# ioam3358 register map
Registers are 32-bit, access not given, no defined reset value unless marked. A register's access mark holds for its fields unless they carry their own. Addresses are absolute; registers are grouped by the start of their names; [hi:lo] are bit positions; {n}, {i} and the like mark numbered series; 'fields as' and 'values as' point back to an identical list.

## I2C2
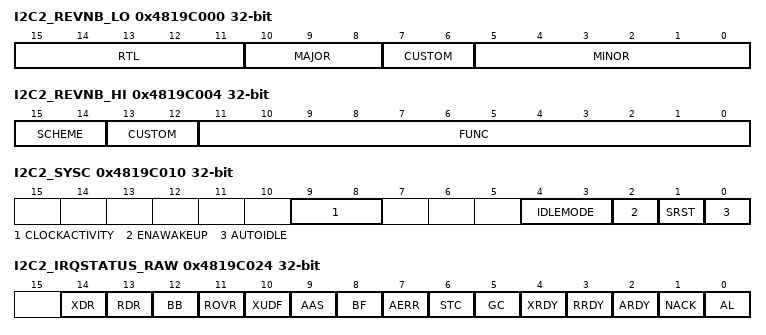
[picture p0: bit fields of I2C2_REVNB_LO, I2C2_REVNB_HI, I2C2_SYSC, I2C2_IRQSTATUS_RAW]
0x4819C000 I2C2_REVNB_LO
  [15:11] RTL, [10:8] MAJOR, [7:6] CUSTOM, [5:0] MINOR
0x4819C004 I2C2_REVNB_HI
  [15:14] SCHEME, [13:12] CUSTOM, [11:0] FUNC
0x4819C010 I2C2_SYSC
  [9:8] CLOCKACTIVITY, [4:3] IDLEMODE, [2] ENAWAKEUP, [1] SRST, [0] AUTOIDLE
0x4819C020 I2C2_EOI
  [0] LINE_NUMBER
0x4819C024 I2C2_IRQSTATUS_RAW
  [14] XDR, [13] RDR, [12] BB, [11] ROVR, [10] XUDF, [9] AAS, [8] BF, [7] AERR, [6] STC, [5] GC, [4] XRDY, [3] RRDY, [2] ARDY, [1] NACK, [0] AL
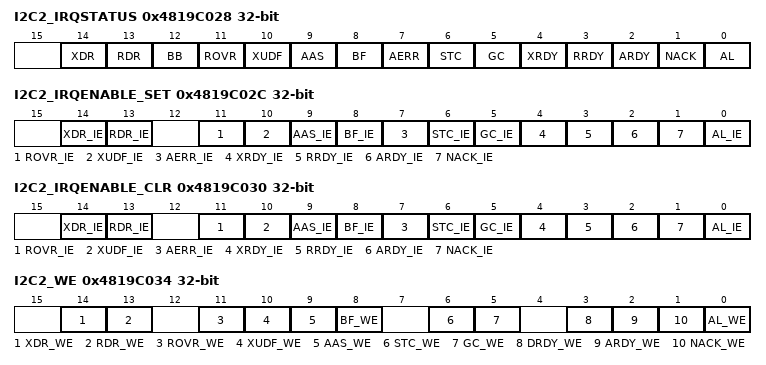
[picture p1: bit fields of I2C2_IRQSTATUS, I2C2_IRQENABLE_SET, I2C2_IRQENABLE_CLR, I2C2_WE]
0x4819C028 I2C2_IRQSTATUS
  fields as I2C2_IRQSTATUS_RAW
0x4819C02C I2C2_IRQENABLE_SET
  [14] XDR_IE, [13] RDR_IE, [11] ROVR_IE, [10] XUDF_IE, [9] AAS_IE, [8] BF_IE, [7] AERR_IE, [6] STC_IE, [5] GC_IE, [4] XRDY_IE, [3] RRDY_IE, [2] ARDY_IE, [1] NACK_IE, [0] AL_IE
0x4819C030 I2C2_IRQENABLE_CLR
  fields as I2C2_IRQENABLE_SET
0x4819C034 I2C2_WE
  [14] XDR_WE, [13] RDR_WE, [11] ROVR_WE, [10] XUDF_WE, [9] AAS_WE, [8] BF_WE, [6] STC_WE, [5] GC_WE, [3] DRDY_WE, [2] ARDY_WE, [1] NACK_WE, [0] AL_WE
0x4819C038 I2C2_DMARXENABLE_SET
  [0] DMARX_ENABLE_SET
0x4819C03C I2C2_DMATXENABLE_SET
  [0] DMATX_ENABLE_SET
0x4819C040 I2C2_DMARXENABLE_CLR
  [0] DMARX_ENABLE_CLEAR
0x4819C044 I2C2_DMATXENABLE_CLR
  [0] DMARX_ENABLE_CLEAR
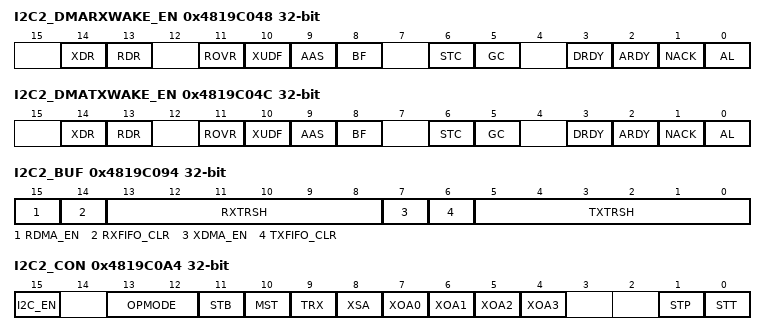
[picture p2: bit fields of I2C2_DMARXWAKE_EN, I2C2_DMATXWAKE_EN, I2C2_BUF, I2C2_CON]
0x4819C048 I2C2_DMARXWAKE_EN
  [14] XDR, [13] RDR, [11] ROVR, [10] XUDF, [9] AAS, [8] BF, [6] STC, [5] GC, [3] DRDY, [2] ARDY, [1] NACK, [0] AL
0x4819C04C I2C2_DMATXWAKE_EN
  fields as I2C2_DMARXWAKE_EN
0x4819C090 I2C2_SYSS
  [0] RDONE
0x4819C094 I2C2_BUF
  [15] RDMA_EN, [14] RXFIFO_CLR, [13:8] RXTRSH, [7] XDMA_EN, [6] TXFIFO_CLR, [5:0] TXTRSH
0x4819C098 I2C2_CNT
  [15:0] DCOUNT
0x4819C09C I2C2_DATA
  [7:0] DATA
0x4819C0A4 I2C2_CON
  [15] I2C_EN, [13:12] OPMODE, [11] STB, [10] MST, [9] TRX, [8] XSA, [7-n] XOA{n} (n=0..3), [1] STP, [0] STT
0x4819C0A8 I2C2_OA
  [9:0] OA
0x4819C0AC I2C2_SA
  [9:0] SA
0x4819C0B0 I2C2_PSC
  [7:0] PSC
0x4819C0B4 I2C2_SCLL
  [7:0] SCLL
0x4819C0B8 I2C2_SCLH
  [7:0] SCLH
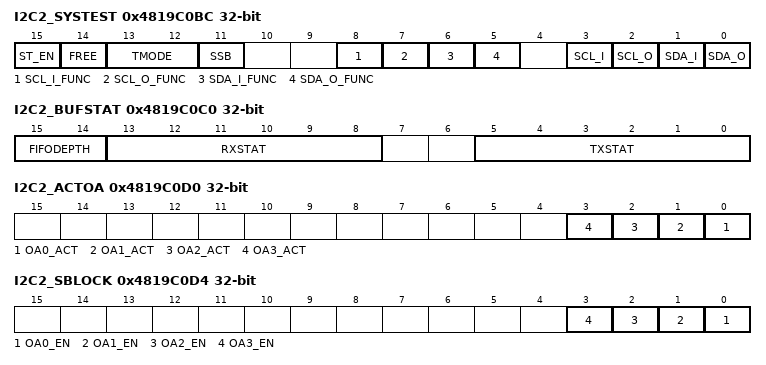
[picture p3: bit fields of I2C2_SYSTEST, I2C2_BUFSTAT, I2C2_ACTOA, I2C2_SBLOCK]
0x4819C0BC I2C2_SYSTEST
  [15] ST_EN, [14] FREE, [13:12] TMODE, [11] SSB, [8] SCL_I_FUNC, [7] SCL_O_FUNC, [6] SDA_I_FUNC, [5] SDA_O_FUNC, [3] SCL_I, [2] SCL_O, [1] SDA_I, [0] SDA_O
0x4819C0C0 I2C2_BUFSTAT
  [15:14] FIFODEPTH, [13:8] RXSTAT, [5:0] TXSTAT
{0x4819C0C0+4i} I2C2_OA{i} (i=1..3)
  [9:0] OA{i}
0x4819C0D0 I2C2_ACTOA
  [n] OA{n}_ACT (n=0..3)
0x4819C0D4 I2C2_SBLOCK
  [n] OA{n}_EN (n=0..3)

## McASP0
0x46000000 McASP0_RBUF
0x46000000 McASP0_XBUF
0x48038000 McASP0_REV
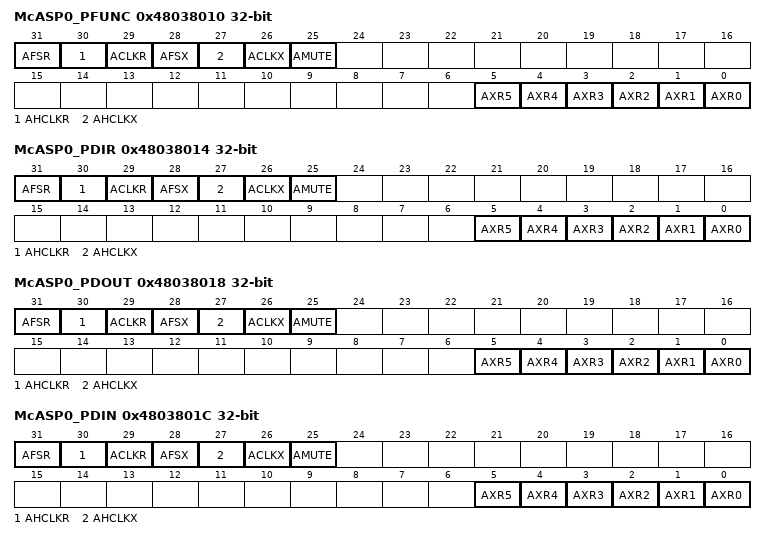
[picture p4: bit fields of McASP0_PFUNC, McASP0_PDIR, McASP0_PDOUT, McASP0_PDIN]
0x48038010 McASP0_PFUNC
  [31] AFSR, [30] AHCLKR, [29] ACLKR, [28] AFSX, [27] AHCLKX, [26] ACLKX, [25] AMUTE, [n] AXR{n} (n=0..5)
0x48038014 McASP0_PDIR
  fields as McASP0_PFUNC
0x48038018 McASP0_PDOUT
  fields as McASP0_PFUNC
0x4803801C McASP0_PDIN
  fields as McASP0_PFUNC
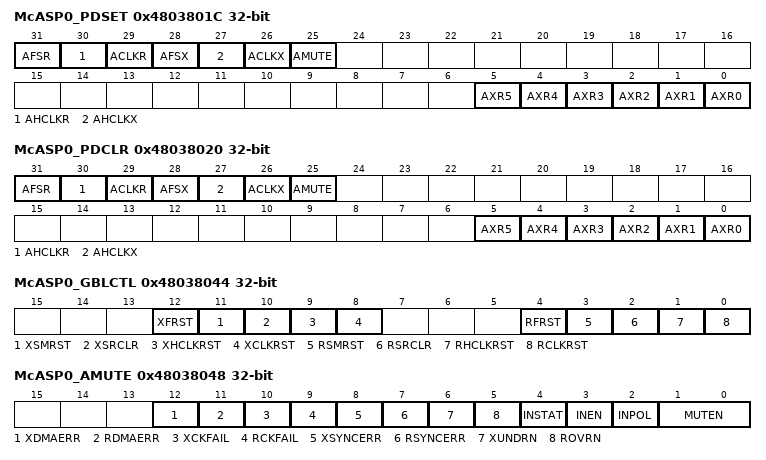
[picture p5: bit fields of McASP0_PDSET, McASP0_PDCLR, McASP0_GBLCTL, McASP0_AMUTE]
0x4803801C McASP0_PDSET
  fields as McASP0_PFUNC
0x48038020 McASP0_PDCLR
  fields as McASP0_PFUNC
0x48038044 McASP0_GBLCTL
  [12] XFRST, [11] XSMRST, [10] XSRCLR, [9] XHCLKRST, [8] XCLKRST, [4] RFRST, [3] RSMRST, [2] RSRCLR, [1] RHCLKRST, [0] RCLKRST
0x48038048 McASP0_AMUTE
  [12] XDMAERR, [11] RDMAERR, [10] XCKFAIL, [9] RCKFAIL, [8] XSYNCERR, [7] RSYNCERR, [6] XUNDRN, [5] ROVRN, [4] INSTAT, [3] INEN, [2] INPOL, [1:0] MUTEN
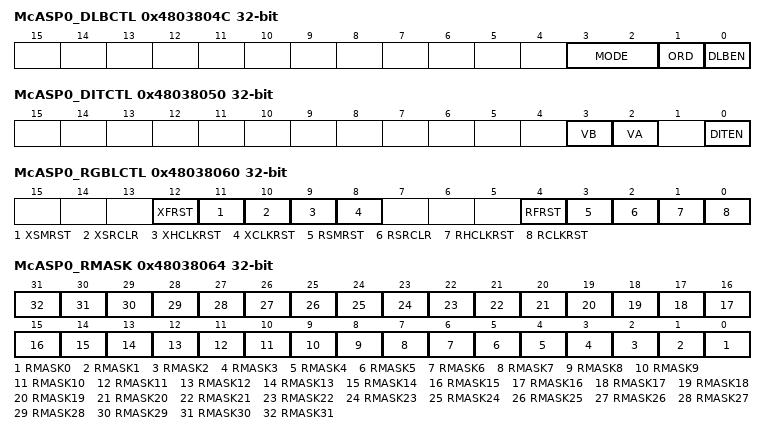
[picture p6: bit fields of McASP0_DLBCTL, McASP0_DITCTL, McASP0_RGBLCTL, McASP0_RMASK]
0x4803804C McASP0_DLBCTL
  [3:2] MODE, [1] ORD, [0] DLBEN
0x48038050 McASP0_DITCTL
  [3] VB, [2] VA, [0] DITEN
0x48038060 McASP0_RGBLCTL
  fields as McASP0_GBLCTL
0x48038064 McASP0_RMASK
  [n] RMASK{n} (n=0..31)
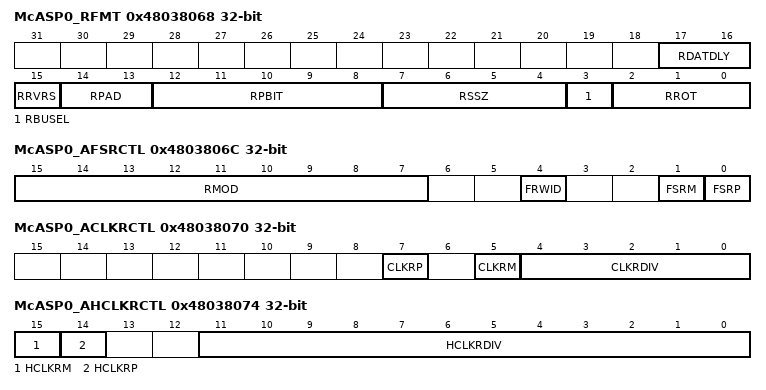
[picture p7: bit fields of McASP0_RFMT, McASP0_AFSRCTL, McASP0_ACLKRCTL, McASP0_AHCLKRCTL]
0x48038068 McASP0_RFMT
  [17:16] RDATDLY, [15] RRVRS, [14:13] RPAD, [12:8] RPBIT, [7:4] RSSZ, [3] RBUSEL, [2:0] RROT
0x4803806C McASP0_AFSRCTL
  [15:7] RMOD, [4] FRWID, [1] FSRM, [0] FSRP
0x48038070 McASP0_ACLKRCTL
  [7] CLKRP, [5] CLKRM, [4:0] CLKRDIV
0x48038074 McASP0_AHCLKRCTL
  [15] HCLKRM, [14] HCLKRP, [11:0] HCLKRDIV
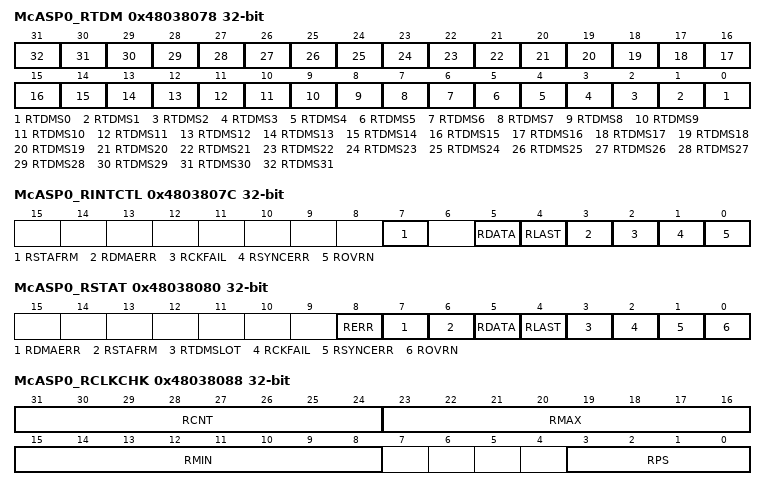
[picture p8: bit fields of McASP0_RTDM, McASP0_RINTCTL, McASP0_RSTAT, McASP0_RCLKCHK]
0x48038078 McASP0_RTDM
  [n] RTDMS{n} (n=0..31)
0x4803807C McASP0_RINTCTL
  [7] RSTAFRM, [5] RDATA, [4] RLAST, [3] RDMAERR, [2] RCKFAIL, [1] RSYNCERR, [0] ROVRN
0x48038080 McASP0_RSTAT
  [8] RERR, [7] RDMAERR, [6] RSTAFRM, [5] RDATA, [4] RLAST, [3] RTDMSLOT, [2] RCKFAIL, [1] RSYNCERR, [0] ROVRN
0x48038084 McASP0_RSLOT
  [8:0] RSLOTCNT
0x48038088 McASP0_RCLKCHK
  [31:24] RCNT, [23:16] RMAX, [15:8] RMIN, [3:0] RPS
0x4803808C McASP0_REVTCTL
  [0] RDATDMA
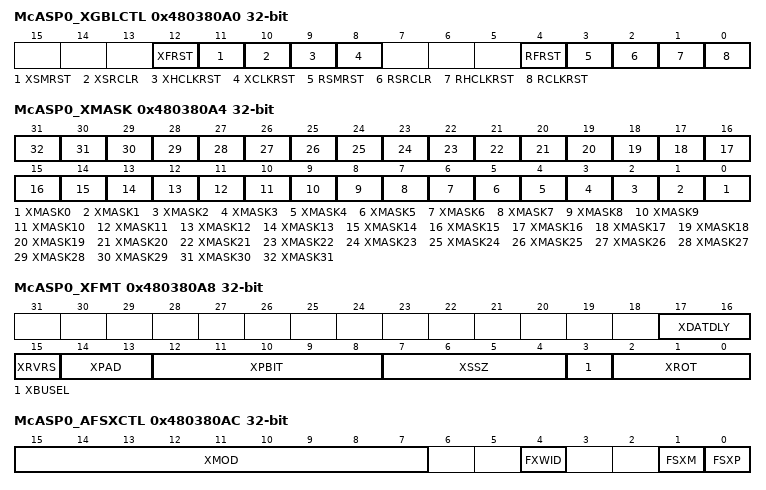
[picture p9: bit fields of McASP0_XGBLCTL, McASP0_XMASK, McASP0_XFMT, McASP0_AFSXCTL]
0x480380A0 McASP0_XGBLCTL
  fields as McASP0_GBLCTL
0x480380A4 McASP0_XMASK
  [n] XMASK{n} (n=0..31)
0x480380A8 McASP0_XFMT
  [17:16] XDATDLY, [15] XRVRS, [14:13] XPAD, [12:8] XPBIT, [7:4] XSSZ, [3] XBUSEL, [2:0] XROT
0x480380AC McASP0_AFSXCTL
  [15:7] XMOD, [4] FXWID, [1] FSXM, [0] FSXP
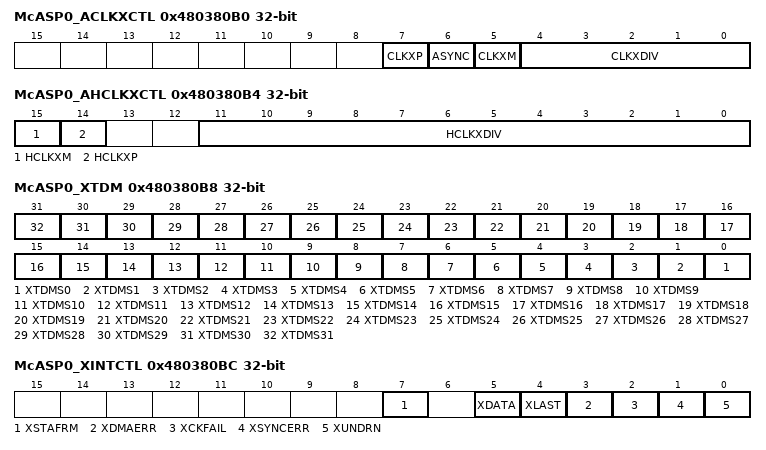
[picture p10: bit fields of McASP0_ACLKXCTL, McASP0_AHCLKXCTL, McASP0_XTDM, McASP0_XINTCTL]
0x480380B0 McASP0_ACLKXCTL
  [7] CLKXP, [6] ASYNC, [5] CLKXM, [4:0] CLKXDIV
0x480380B4 McASP0_AHCLKXCTL
  [15] HCLKXM, [14] HCLKXP, [11:0] HCLKXDIV
0x480380B8 McASP0_XTDM
  [n] XTDMS{n} (n=0..31)
0x480380BC McASP0_XINTCTL
  [7] XSTAFRM, [5] XDATA, [4] XLAST, [3] XDMAERR, [2] XCKFAIL, [1] XSYNCERR, [0] XUNDRN
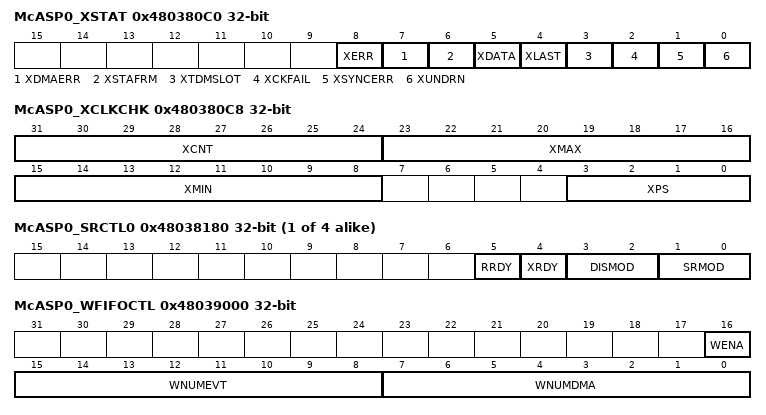
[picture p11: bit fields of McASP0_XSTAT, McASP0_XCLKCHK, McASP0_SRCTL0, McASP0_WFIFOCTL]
0x480380C0 McASP0_XSTAT
  [8] XERR, [7] XDMAERR, [6] XSTAFRM, [5] XDATA, [4] XLAST, [3] XTDMSLOT, [2] XCKFAIL, [1] XSYNCERR, [0] XUNDRN
0x480380C4 McASP0_XSLOT
  [9:0] XSLOTCNT
0x480380C8 McASP0_XCLKCHK
  [31:24] XCNT, [23:16] XMAX, [15:8] XMIN, [3:0] XPS
0x480380CC McASP0_XEVTCTL
  [0] XDATDMA
{0x48038100+4i} McASP0_DITCSRA{i} (i=0..5)
{0x48038118+4i} McASP0_DITCSRB{i} (i=0..5)
{0x48038130+4i} McASP0_DITUDRA{i} (i=0..5)
{0x48038148+4i} McASP0_DITUDRB{i} (i=0..5)
{0x48038180+4i} McASP0_SRCTL{i} (i=0..3)
  [5] RRDY, [4] XRDY, [3:2] DISMOD, [1:0] SRMOD
{0x48038200+4i} McASP0_XBUF{i} (i=0..3)
{0x48038280+4i} McASP0_RBUF{i} (i=0..3)
0x48039000 McASP0_WFIFOCTL
  [16] WENA, [15:8] WNUMEVT, [7:0] WNUMDMA
0x48039004 McASP0_WFIFOSTS
  [7:0] WLVL
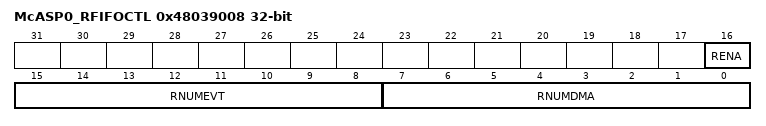
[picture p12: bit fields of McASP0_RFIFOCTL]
0x48039008 McASP0_RFIFOCTL
  [16] RENA, [15:8] RNUMEVT, [7:0] RNUMDMA
0x4803900C McASP0_RFIFOSTS
  [7:0] RLVL
